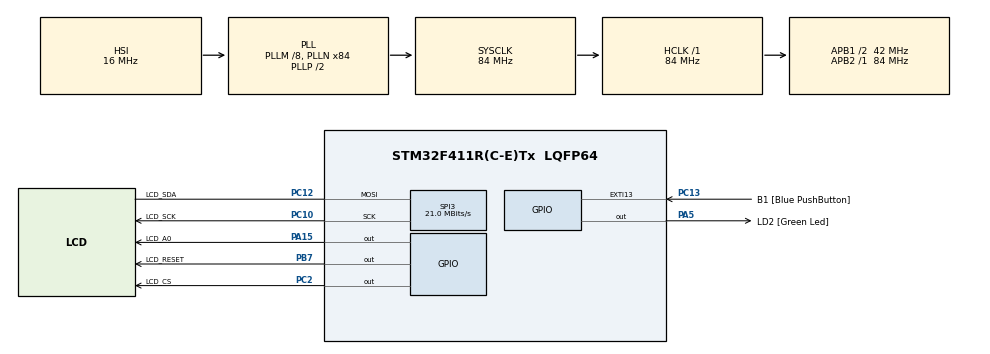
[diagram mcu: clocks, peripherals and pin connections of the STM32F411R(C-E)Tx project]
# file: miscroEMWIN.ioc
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Dma.Request0=SPI3_RX
Dma.Request1=SPI3_TX
Dma.SPI3_RX.0.Direction=DMA_PERIPH_TO_MEMORY
Dma.SPI3_RX.0.FIFOMode=DMA_FIFOMODE_DISABLE
Dma.SPI3_RX.0.Instance=DMA1_Stream0
Dma.SPI3_RX.0.MemDataAlignment=DMA_MDATAALIGN_HALFWORD
Dma.SPI3_RX.0.MemInc=DMA_MINC_ENABLE
Dma.SPI3_RX.0.Mode=DMA_NORMAL
Dma.SPI3_RX.0.PeriphDataAlignment=DMA_PDATAALIGN_HALFWORD
Dma.SPI3_RX.0.PeriphInc=DMA_PINC_DISABLE
Dma.SPI3_RX.0.Priority=DMA_PRIORITY_MEDIUM
Dma.SPI3_TX.1.Direction=DMA_MEMORY_TO_PERIPH
Dma.SPI3_TX.1.FIFOMode=DMA_FIFOMODE_DISABLE
Dma.SPI3_TX.1.Instance=DMA1_Stream5
Dma.SPI3_TX.1.MemDataAlignment=DMA_MDATAALIGN_HALFWORD
Dma.SPI3_TX.1.MemInc=DMA_MINC_DISABLE
Dma.SPI3_TX.1.Mode=DMA_NORMAL
Dma.SPI3_TX.1.PeriphDataAlignment=DMA_PDATAALIGN_HALFWORD
Dma.SPI3_TX.1.PeriphInc=DMA_PINC_DISABLE
Dma.SPI3_TX.1.Priority=DMA_PRIORITY_MEDIUM
Mcu.Family=STM32F4
Mcu.Name=STM32F411R(C-E)Tx
Mcu.Package=LQFP64
NVIC.DMA1_Stream0_IRQn=true\:0\:0\:false\:false\:true\:false
NVIC.DMA1_Stream5_IRQn=true\:0\:0\:false\:false\:true\:false
NVIC.PriorityGroup=NVIC_PRIORITYGROUP_0
NVIC.SPI3_IRQn=true\:0\:0\:false\:false\:true\:true
PA13.GPIO_Label=TMS
PA13.Signal=SYS_JTMS-SWDIO
PA14.GPIO_Label=TCK
PA14.Signal=SYS_JTCK-SWCLK
PA15.GPIO_Label=LCD_A0
PA15.GPIO_Speed=GPIO_SPEED_FREQ_VERY_HIGH
PA15.Signal=GPIO_Output
PA2.GPIO_Label=USART_TX
PA2.Signal=USART2_TX
PA3.GPIO_Label=USART_RX
PA3.Signal=USART2_RX
PA5.GPIO_Label=LD2 [Green Led]
PA5.GPIO_Speed=GPIO_SPEED_FREQ_VERY_HIGH
PA5.PinState=GPIO_PIN_RESET
PA5.Signal=GPIO_Output
PB3.GPIO_Label=SWO
PB3.Signal=SYS_JTDO-SWO
PB7.GPIO_Label=LCD_RESET
PB7.GPIO_Speed=GPIO_SPEED_FREQ_VERY_HIGH
PB7.Signal=GPIO_Output
PC10.GPIO_Label=LCD_SCK
PC10.Mode=Simplex_Bidirectional_Master
PC10.Signal=SPI3_SCK
PC12.GPIO_Label=LCD_SDA
PC12.Mode=Simplex_Bidirectional_Master
PC12.Signal=SPI3_MOSI
PC13-ANTI_TAMP.GPIO_Label=B1 [Blue PushButton]
PC13-ANTI_TAMP.GPIO_ModeDefaultEXTI=GPIO_MODE_IT_FALLING
PC13-ANTI_TAMP.Signal=GPXTI13
PC14-OSC32_IN.Signal=RCC_OSC32_IN
PC15-OSC32_OUT.Signal=RCC_OSC32_OUT
PC2.GPIO_Label=LCD_CS
PC2.GPIO_Speed=GPIO_SPEED_FREQ_VERY_HIGH
PC2.Signal=GPIO_Output
PH0\ -\ OSC_IN.Signal=RCC_OSC_IN
PH1\ -\ OSC_OUT.Signal=RCC_OSC_OUT
ProjectManager.HeapSize=0x200
ProjectManager.StackSize=0x400
ProjectManager.TargetToolchain=SW4STM32
RCC.48MHZClocksFreq_Value=42000000
RCC.AHBFreq_Value=84000000
RCC.APB1CLKDivider=RCC_HCLK_DIV2
RCC.APB1Freq_Value=42000000
RCC.APB1TimFreq_Value=84000000
RCC.APB2Freq_Value=84000000
RCC.APB2TimFreq_Value=84000000
RCC.CortexFreq_Value=84000000
RCC.FLatency-AdvancedSettings=FLASH_LATENCY_2
RCC.HCLKFreq_Value=84000000
RCC.HSE_VALUE=8000000
RCC.HSI_VALUE=16000000
RCC.LSE_VALUE=32768
RCC.PLLM=8
RCC.PLLN=84
RCC.SYSCLKFreq_VALUE=84000000
RCC.SYSCLKSource=RCC_SYSCLKSOURCE_PLLCLK
RCC.VCOOutputFreq_Value=168000000
SPI3.BaudRatePrescaler=SPI_BAUDRATEPRESCALER_2
SPI3.CalculateBaudRate=21.0 MBits/s
SPI3.Direction=SPI_DIRECTION_1LINE
SPI3.Mode=SPI_MODE_MASTER
SPI3.VirtualType=VM_MASTER
VP_CRC_VS_CRC.Mode=CRC_Activate
board=NUCLEO-F411RE

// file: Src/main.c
/**
  ******************************************************************************
  * File Name          : main.c
  * Description        : Main program body
  ******************************************************************************
  ** This notice applies to any and all portions of this file
  * that are not between comment pairs USER CODE BEGIN and
  * USER CODE END. Other portions of this file, whether
  * inserted by the user or by software development tools
  * are owned by their respective copyright owners.
  *
  * COPYRIGHT(c) 2017 STMicroelectronics
  *
  * Redistribution and use in source and binary forms, with or without modification,
  * are permitted provided that the following conditions are met:
  *   1. Redistributions of source code must retain the above copyright notice,
  *      this list of conditions and the following disclaimer.
  *   2. Redistributions in binary form must reproduce the above copyright notice,
  *      this list of conditions and the following disclaimer in the documentation
  *      and/or other materials provided with the distribution.
  *   3. Neither the name of STMicroelectronics nor the names of its contributors
  *      may be used to endorse or promote products derived from this software
  *      without specific prior written permission.
  *
  * THIS SOFTWARE IS PROVIDED BY THE COPYRIGHT HOLDERS AND CONTRIBUTORS "AS IS"
  * AND ANY EXPRESS OR IMPLIED WARRANTIES, INCLUDING, BUT NOT LIMITED TO, THE
  * IMPLIED WARRANTIES OF MERCHANTABILITY AND FITNESS FOR A PARTICULAR PURPOSE ARE
  * DISCLAIMED. IN NO EVENT SHALL THE COPYRIGHT HOLDER OR CONTRIBUTORS BE LIABLE
  * FOR ANY DIRECT, INDIRECT, INCIDENTAL, SPECIAL, EXEMPLARY, OR CONSEQUENTIAL
  * DAMAGES (INCLUDING, BUT NOT LIMITED TO, PROCUREMENT OF SUBSTITUTE GOODS OR
  * SERVICES; LOSS OF USE, DATA, OR PROFITS; OR BUSINESS INTERRUPTION) HOWEVER
  * CAUSED AND ON ANY THEORY OF LIABILITY, WHETHER IN CONTRACT, STRICT LIABILITY,
  * OR TORT (INCLUDING NEGLIGENCE OR OTHERWISE) ARISING IN ANY WAY OUT OF THE USE
  * OF THIS SOFTWARE, EVEN IF ADVISED OF THE POSSIBILITY OF SUCH DAMAGE.
  *
  ******************************************************************************
  */
#include "main.h"
#include "stm32f4xx_hal.h"
#include "crc.h"
#include "dma.h"
#include "spi.h"
#include "gpio.h"

/* USER CODE BEGIN Includes */
#include "GUI.h"
/* USER CODE END Includes */

/* USER CODE BEGIN PV */
/* Private variables ---------------------------------------------------------*/

/* USER CODE END PV */

void SystemClock_Config(void);

/* USER CODE BEGIN PFP */
/* Private function prototypes -----------------------------------------------*/

/* USER CODE END PFP */

int main(void)
{

  /* MCU Configuration----------------------------------------------------------*/

  /* Reset of all peripherals, Initializes the Flash interface and the Systick. */
  HAL_Init();

  /* Configure the system clock */
  SystemClock_Config();

  /* Initialize all configured peripherals */
  MX_GPIO_Init();
  MX_DMA_Init();
  MX_SPI3_Init();
  MX_CRC_Init();

  /* USER CODE BEGIN 2 */
  GUI_Init();
  GUI_DispString("Test");
  /* USER CODE END 2 */

  /* Infinite loop */
  while (1)
  {

  }

}

/** System Clock Configuration
*/
void SystemClock_Config(void)
{

  RCC_OscInitTypeDef RCC_OscInitStruct;
  RCC_ClkInitTypeDef RCC_ClkInitStruct;

    /**Configure the main internal regulator output voltage
    */
  __HAL_RCC_PWR_CLK_ENABLE();

  __HAL_PWR_VOLTAGESCALING_CONFIG(PWR_REGULATOR_VOLTAGE_SCALE1);

    /**Initializes the CPU, AHB and APB busses clocks
    */
  RCC_OscInitStruct.OscillatorType = RCC_OSCILLATORTYPE_HSI;
  RCC_OscInitStruct.HSIState = RCC_HSI_ON;
  RCC_OscInitStruct.HSICalibrationValue = 16;
  RCC_OscInitStruct.PLL.PLLState = RCC_PLL_ON;
  RCC_OscInitStruct.PLL.PLLSource = RCC_PLLSOURCE_HSI;
  RCC_OscInitStruct.PLL.PLLM = 8;
  RCC_OscInitStruct.PLL.PLLN = 84;
  RCC_OscInitStruct.PLL.PLLP = RCC_PLLP_DIV2;
  RCC_OscInitStruct.PLL.PLLQ = 4;
  if (HAL_RCC_OscConfig(&RCC_OscInitStruct) != HAL_OK)
  {
    _Error_Handler(__FILE__, __LINE__);
  }

    /**Initializes the CPU, AHB and APB busses clocks
    */
  RCC_ClkInitStruct.ClockType = RCC_CLOCKTYPE_HCLK|RCC_CLOCKTYPE_SYSCLK
                              |RCC_CLOCKTYPE_PCLK1|RCC_CLOCKTYPE_PCLK2;
  RCC_ClkInitStruct.SYSCLKSource = RCC_SYSCLKSOURCE_PLLCLK;
  RCC_ClkInitStruct.AHBCLKDivider = RCC_SYSCLK_DIV1;
  RCC_ClkInitStruct.APB1CLKDivider = RCC_HCLK_DIV2;
  RCC_ClkInitStruct.APB2CLKDivider = RCC_HCLK_DIV1;

  if (HAL_RCC_ClockConfig(&RCC_ClkInitStruct, FLASH_LATENCY_2) != HAL_OK)
  {
    _Error_Handler(__FILE__, __LINE__);
  }

    /**Configure the Systick interrupt time
    */
  HAL_SYSTICK_Config(HAL_RCC_GetHCLKFreq()/1000);

    /**Configure the Systick
    */
  HAL_SYSTICK_CLKSourceConfig(SYSTICK_CLKSOURCE_HCLK);

  /* SysTick_IRQn interrupt configuration */
  HAL_NVIC_SetPriority(SysTick_IRQn, 0, 0);
}

void _Error_Handler(char * file, int line)
{
  while(1)
  {
  }
}

/************************ (C) COPYRIGHT STMicroelectronics *****END OF FILE****/
